VERSION ""
NS_ :

BS_:
BU_: RVCController RVCNode

// DM_RV from SA=0x9D (0x80000000|0x18FECA9D = 2566834845)
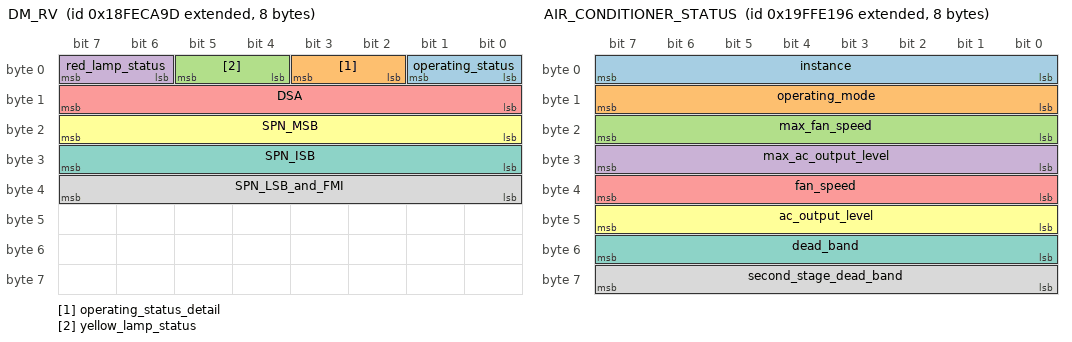
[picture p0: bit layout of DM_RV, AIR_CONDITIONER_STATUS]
BO_ 2566834845 DM_RV: 8 RVCNode
    SG_ operating_status           :  0|2@1+ (1,0)   [0|3]    "" RVCController
    SG_ operating_status_detail    :  2|2@1+ (1,0)   [0|3]    "" RVCController
    SG_ yellow_lamp_status         :  4|2@1+ (1,0)   [0|3]    "" RVCController
    SG_ red_lamp_status            :  6|2@1+ (1,0)   [0|3]    "" RVCController
    SG_ DSA                         :  8|8@1+ (1,0)   [0|255]  "" RVCController
    SG_ SPN_MSB                     : 16|8@1+ (1,0)   [0|255]  "" RVCController
    SG_ SPN_ISB                     : 24|8@1+ (1,0)   [0|255]  "" RVCController
    SG_ SPN_LSB_and_FMI             : 32|8@1+ (1,0)   [0|255]  "" RVCController

// AIR_CONDITIONER_STATUS from SA=0x96 (0x80000000|0x19FFE196 = 2583683478)
BO_ 2583683478 AIR_CONDITIONER_STATUS: 8 RVCNode
    SG_ instance                   :  0|8@1+ (1,0)   [0|255] "" RVCController
    SG_ operating_mode             :  8|8@1+ (1,0)   [0|255] "" RVCController
    SG_ max_fan_speed              : 16|8@1+ (0.5,0) [0|100] "%" RVCController
    SG_ max_ac_output_level        : 24|8@1+ (0.5,0) [0|100] "%" RVCController
    SG_ fan_speed                  : 32|8@1+ (0.5,0) [0|100] "%" RVCController
    SG_ ac_output_level            : 40|8@1+ (0.5,0) [0|100] "%" RVCController
    SG_ dead_band                  : 48|8@1+ (0.1,0) [0|25]  "°C" RVCController
    SG_ second_stage_dead_band     : 56|8@1+ (0.1,0) [0|25]  "°C" RVCController

// DM_RV from SA=0x9C (0x80000000|0x18FECA9C = 2566834844)
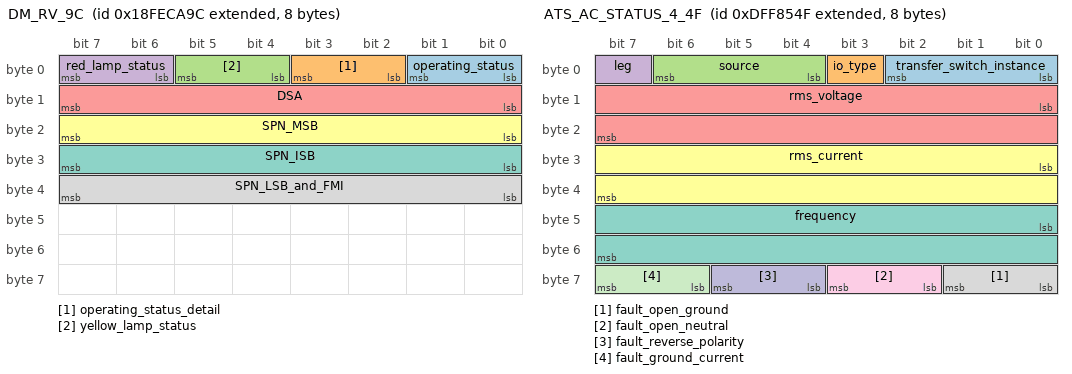
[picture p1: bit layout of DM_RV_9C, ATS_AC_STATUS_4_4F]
BO_ 2566834844 DM_RV_9C: 8 RVCNode
    SG_ operating_status           :  0|2@1+ (1,0)   [0|3]   "" RVCController
    SG_ operating_status_detail    :  2|2@1+ (1,0)   [0|3]   "" RVCController
    SG_ yellow_lamp_status         :  4|2@1+ (1,0)   [0|3]   "" RVCController
    SG_ red_lamp_status            :  6|2@1+ (1,0)   [0|3]   "" RVCController
    SG_ DSA                         :  8|8@1+ (1,0)   [0|255] "" RVCController
    SG_ SPN_MSB                     : 16|8@1+ (1,0)   [0|255] "" RVCController
    SG_ SPN_ISB                     : 24|8@1+ (1,0)   [0|255] "" RVCController
    SG_ SPN_LSB_and_FMI             : 32|8@1+ (1,0)   [0|255] "" RVCController

// ATS_AC_STATUS_4 from SA=0x4F (0x80000000|0x0DFF854F = 2382333263)
BO_ 2382333263 ATS_AC_STATUS_4_4F: 8 RVCNode
    SG_ transfer_switch_instance   :  0|3@1+ (1,0) [0|7]   "" RVCController
    SG_ io_type                     :  3|1@1+ (1,0) [0|1]   "" RVCController
    SG_ source                      :  4|3@1+ (1,0) [0|7]   "" RVCController
    SG_ leg                         :  7|1@1+ (1,0) [0|1]   "" RVCController
    SG_ rms_voltage                 :  8|16@1+ (0.1,0) [0|6553.5] "Vac" RVCController
    SG_ rms_current                 : 24|16@1+ (0.1,0) [0|6553.5] "Aac" RVCController
    SG_ frequency                   : 40|16@1+ (0.0078125,0) [0|500] "Hz" RVCController
    SG_ fault_open_ground           : 56|2@1+ (1,0) [0|3]   "" RVCController
    SG_ fault_open_neutral          : 58|2@1+ (1,0) [0|3]   "" RVCController
    SG_ fault_reverse_polarity      : 60|2@1+ (1,0) [0|3]   "" RVCController
    SG_ fault_ground_current        : 62|2@1+ (1,0) [0|3]   "" RVCController
